# MKL28T7_CORE1 register map
Vendor: Freescale Semiconductor, Inc.; Series: Kinetis_L; File version: 1.6
CPU: CM0PLUS r0p0, little endian, no MPU, no FPU, VTOR, 2 interrupt priority bits
Registers are 32-bit, read-write, reset 0x0 unless marked. A register's access mark holds for its fields unless they carry their own. Offsets are from the block's base; [hi:lo] are bit positions; {n}, {i} and the like mark numbered series; 'fields as' and 'values as' point back to an identical list.

## CRC — Cyclic Redundancy Check
Base 0x40078000; register names take the prefix CRC_
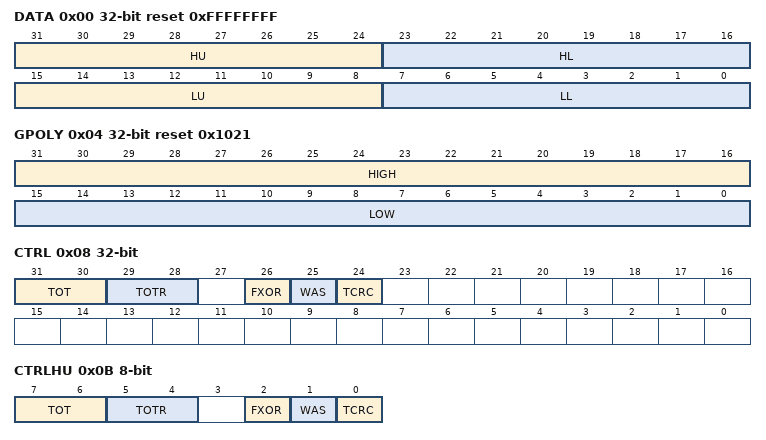
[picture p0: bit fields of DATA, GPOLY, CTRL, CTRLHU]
0x00 DATA reset 0xFFFFFFFF (CRC view) — CRC Data register
  [31:24] HU — CRC High Upper Byte
  [23:16] HL — CRC High Lower Byte
  [15:8] LU — CRC Low Upper Byte
  [7:0] LL — CRC Low Lower Byte
0x00 DATAL 16-bit reset 0xFFFF (CRC view) — CRC_DATAL register.
  [15:0] DATAL — DATAL stores the lower 16 bits of the 16/32 bit CRC
0x00 DATALL 8-bit reset 0xFF (CRC view) — CRC_DATALL register.
  [7:0] DATALL — CRCLL stores the first 8 bits of the 32 bit DATA
0x01 DATALU 8-bit reset 0xFF — CRC_DATALU register.
  [7:0] DATALU — DATALL stores the second 8 bits of the 32 bit CRC
0x02 DATAH 16-bit reset 0xFFFF (CRC view) — CRC_DATAH register.
  [15:0] DATAH — DATAH stores the high 16 bits of the 16/32 bit CRC
0x02 DATAHL 8-bit reset 0xFF (CRC view) — CRC_DATAHL register.
  [7:0] DATAHL — DATAHL stores the third 8 bits of the 32 bit CRC
0x03 DATAHU 8-bit reset 0xFF — CRC_DATAHU register.
  [7:0] DATAHU — DATAHU stores the fourth 8 bits of the 32 bit CRC
0x04 GPOLY reset 0x1021 (CRC view) — CRC Polynomial register
  [31:16] HIGH — High Polynominal Half-word
  [15:0] LOW — Low Polynominal Half-word
0x04 GPOLYL 16-bit reset 0xFFFF (CRC view) — CRC_GPOLYL register.
  [15:0] GPOLYL — POLYL stores the lower 16 bits of the 16/32 bit CRC polynomial value
0x04 GPOLYLL 8-bit reset 0xFF (CRC view) — CRC_GPOLYLL register.
  [7:0] GPOLYLL — POLYLL stores the first 8 bits of the 32 bit CRC
0x05 GPOLYLU 8-bit reset 0xFF — CRC_GPOLYLU register.
  [7:0] GPOLYLU — POLYLL stores the second 8 bits of the 32 bit CRC
0x06 GPOLYH 16-bit reset 0xFFFF (CRC view) — CRC_GPOLYH register.
  [15:0] GPOLYH — POLYH stores the high 16 bits of the 16/32 bit CRC polynomial value
0x06 GPOLYHL 8-bit reset 0xFF (CRC view) — CRC_GPOLYHL register.
  [7:0] GPOLYHL — POLYHL stores the third 8 bits of the 32 bit CRC
0x07 GPOLYHU 8-bit reset 0xFF — CRC_GPOLYHU register.
  [7:0] GPOLYHU — POLYHU stores the fourth 8 bits of the 32 bit CRC
0x08 CTRL — CRC Control register
  [31:30] TOT — Type Of Transpose For Writes
    0=No transposition; 1=Bits in bytes are transposed; bytes are not transposed; 2=Both bits in bytes and bytes are transposed; 3=Only bytes are transposed; no bits in a byte are transposed
  [29:28] TOTR — Type Of Transpose For Read
    values as TOT
  [26] FXOR — Complement Read Of CRC Data Register
    0=No XOR on reading; 1=Invert or complement the read value of the CRC Data register
  [25] WAS — Write CRC Data Register As Seed
    0=Writes to the CRC data register are data values; 1=Writes to the CRC data register are seed values
  [24] TCRC — Width of CRC protocol.
    0=16-bit CRC protocol; 1=32-bit CRC protocol
0x0B CTRLHU 8-bit — CRC_CTRLHU register.
  [7:6] TOT
    0=No Transposition; 1=Bits in bytes are transposed, bytes are not transposed; 2=Both bits in bytes and bytes are transposed; 3=Only bytes are transposed; no bits in a byte are transposed
  [5:4] TOTR
    values as TOT
  [2] FXOR
    0=No XOR on reading; 1=Invert or complement the read value of CRC data register
  [1] WAS
    0=Writes to CRC data register are data values; 1=Writes to CRC data reguster are seed values
  [0] TCRC
    0=16-bit CRC protocol; 1=32-bit CRC protocol

## RFSYS — System register file
Base 0x4007C000; register names take the prefix RFSYS_
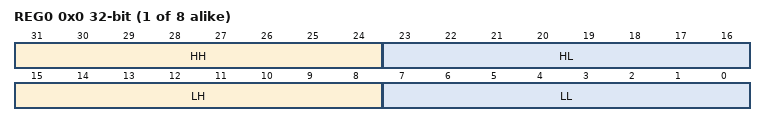
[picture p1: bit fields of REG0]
{0x0+4i} REG{i} (i=0..7) — Register file register
  [31:24] HH — High higher byte
  [23:16] HL — High lower byte
  [15:8] LH — Low higher byte
  [7:0] LL — Low lower byte

## PMC — Power Management Controller
Base 0x4007D000; register names take the prefix PMC_
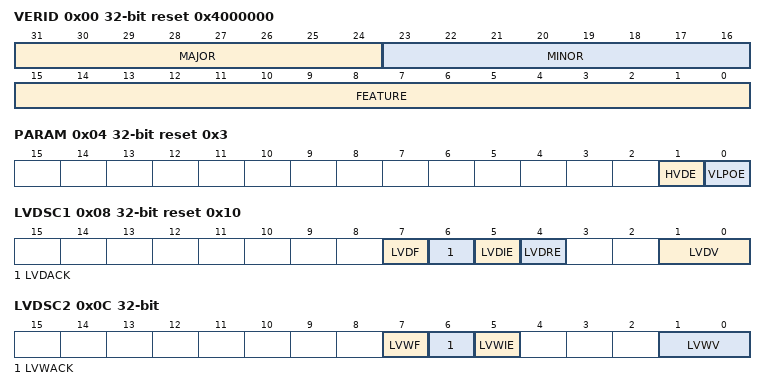
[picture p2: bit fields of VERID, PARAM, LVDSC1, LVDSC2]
0x00 VERID ro reset 0x4000000 — Version ID register
  [31:24] MAJOR — Major Version Number
  [23:16] MINOR — Minor Version Number
  [15:0] FEATURE — Feature Specification Number
    0=Standard features implemented
0x04 PARAM ro reset 0x3 — Parameter register
  [1] HVDE — HVD Enabled
  [0] VLPOE — VLPO Enable
0x08 LVDSC1 reset 0x10 — Low Voltage Detect Status And Control 1 register
  [7] LVDF ro — Low-Voltage Detect Flag
    0=Low-voltage event not detected; 1=Low-voltage event detected
  [6] LVDACK wo — Low-Voltage Detect Acknowledge
  [5] LVDIE — Low-Voltage Detect Interrupt Enable
    0=Hardware interrupt disabled (use polling); 1=Request a hardware interrupt when LVDF = 1
  [4] LVDRE — Low-Voltage Detect Reset Enable
    0=LVDF does not generate hardware resets; 1=Force an MCU reset when LVDF = 1
  [1:0] LVDV — Low-Voltage Detect Voltage Select
    0=Low trip point selected (V LVD = V LVDL ); 1=High trip point selected (V LVD = V LVDH )
0x0C LVDSC2 — Low Voltage Detect Status And Control 2 register
  [7] LVWF ro — Low-Voltage Warning Flag
    0=Low-voltage warning event not detected; 1=Low-voltage warning event detected
  [6] LVWACK wo — Low-Voltage Warning Acknowledge
  [5] LVWIE — Low-Voltage Warning Interrupt Enable
    0=Hardware interrupt disabled (use polling); 1=Request a hardware interrupt when LVWF = 1
  [1:0] LVWV — Low-Voltage Warning Voltage Select
    0=Low trip point selected (VLVW = VLVW1); 1=Mid 1 trip point selected (VLVW = VLVW2); 2=Mid 2 trip point selected (VLVW = VLVW3); 3=High trip point selected (VLVW = VLVW4)
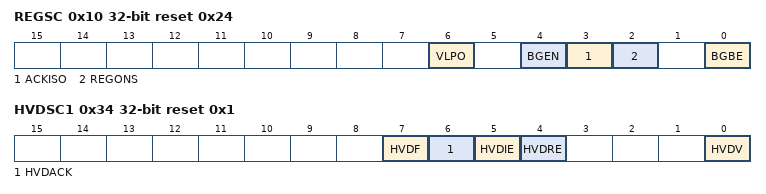
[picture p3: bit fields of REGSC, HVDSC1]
0x10 REGSC reset 0x24 — Regulator Status And Control register
  [6] VLPO — VLPx Option
    0=Operating frequencies and SCG clocking modes are restricted during VLPx modes as listed in the Power Management chapter; 1=If BGEN is also set, operating frequencies and SCG clocking modes are unrestricted during VLPx modes. Note that flash access frequency is still restricted however.
  [4] BGEN — Bandgap Enable In VLPx Operation
    0=Bandgap voltage reference is disabled in VLPx , LLS , and VLLSx modes; 1=Bandgap voltage reference is enabled in VLPx , LLS , and VLLSx modes
  [3] ACKISO — Acknowledge Isolation
    0=Peripherals and I/O pads are in normal run state; 1=Certain peripherals and I/O pads are in an isolated and latched state
  [2] REGONS ro — Regulator In Run Regulation Status
    0=Regulator is in stop regulation or in transition to/from it; 1=Regulator is in run regulation
  [0] BGBE — Bandgap Buffer Enable
    0=Bandgap buffer not enabled; 1=Bandgap buffer enabled
0x34 HVDSC1 reset 0x1 — High Voltage Detect Status And Control 1 register
  [7] HVDF ro — High-Voltage Detect Flag
    0=High-voltage event not detected; 1=High-voltage event detected
  [6] HVDACK wo — High-Voltage Detect Acknowledge
  [5] HVDIE — High-Voltage Detect Interrupt Enable
    0=Hardware interrupt disabled (use polling); 1=Request a hardware interrupt when HVDF = 1
  [4] HVDRE — High-Voltage Detect Reset Enable
    0=HVDF does not generate hardware resets; 1=Force an MCU reset when HVDF = 1
  [0] HVDV — High-Voltage Detect Voltage Select
    0=Low trip point selected (V HVD = V HVDL ); 1=High trip point selected (V HVD = V HVDH )
